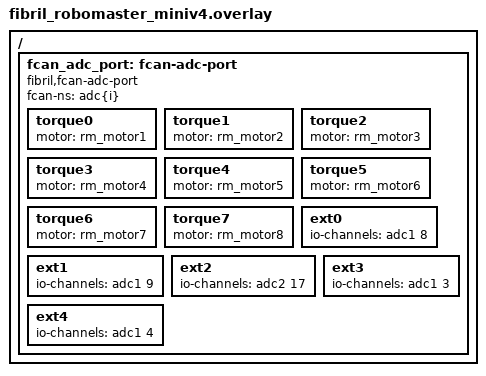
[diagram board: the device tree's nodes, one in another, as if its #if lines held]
/*
 * Copyright (c) 2026
 * SPDX-License-Identifier: Apache-2.0
 *
 * Every input a Mini V4 can watch, at a port number fixed for the board:
 * CanMotorMbed's 13 miniv4 ports. A torque port reads as no sample while its
 * motor is not fitted, offline or stale; a fitted motor reports its current
 * whether or not this image drives it. An analog pin left open reads as a
 * floating level. No motor watches a port unless its adc/port says so, so
 * the numbering never depends on which other snippets are layered, and an
 * adc/port set on the ROS side keeps its meaning.
 */

#include <fibril/robomaster_miniv4/robomaster.dtsi>
#include <fibril/robomaster_miniv4/adc.dtsi>

#ifdef FIBRIL_CLAIM_FCAN_ADC_PORT
#error "FCAN_ADC_PORT claimed twice; miniv4-adc is one claimant"
#endif
#define FIBRIL_CLAIM_FCAN_ADC_PORT 1

/ {
    fcan_adc_port: fcan-adc-port {
        compatible = "fibril,fcan-adc-port";

        /* adc0..adc12, the names can_md_controller gave the thresholds. */
        fcan-ns = "adc{i}";
        status = "okay";

        /* Ports 0..7: the torque RoboMaster motors 1..8 report. */
        torque0 { motor = <&rm_motor1>; };
        torque1 { motor = <&rm_motor2>; };
        torque2 { motor = <&rm_motor3>; };
        torque3 { motor = <&rm_motor4>; };
        torque4 { motor = <&rm_motor5>; };
        torque5 { motor = <&rm_motor6>; };
        torque6 { motor = <&rm_motor7>; };
        torque7 { motor = <&rm_motor8>; };

        /* Ports 8..12: ADC__0..ADC__4 (PC2, PC3, PA4, PA2, PA3). */
        ext0 { io-channels = <&adc1 8>; };
        ext1 { io-channels = <&adc1 9>; };
        ext2 { io-channels = <&adc2 17>; };
        ext3 { io-channels = <&adc1 3>; };
        ext4 { io-channels = <&adc1 4>; };
    };
};
